# nrf9160 register map
Vendor: Nordic Semiconductor; Series: nrf91; File version: 1
CPU: CM33 r0p4, little endian, MPU, FPU, 3 interrupt priority bits, 69 interrupts
Registers are 32-bit, read-write, reset 0x0 unless marked. A register's access mark holds for its fields unless they carry their own. Offsets are from the block's base; [hi:lo] are bit positions; lines under a group give offsets from that group; {n}, {i} and the like mark numbered series; 'fields as' and 'values as' point back to an identical list.

## TAD_S — Trace and debug control
Base 0xE0080000
0x00 CLOCKSTART wo — Start all trace and debug clocks.
  [0] START
    1=Start all trace and debug clocks
0x04 CLOCKSTOP wo — Stop all trace and debug clocks.
  [0] STOP
    1=Stop all trace and debug clocks
0x500 ENABLE — Enable debug domain and acquire selected GPIOs
  [0] ENABLE
    0=DISABLED (Disable debug domain and release selected GPIOs); 1=ENABLED (Enable debug domain and acquire selected GPIOs)
0x504 PSEL group — Unspecified
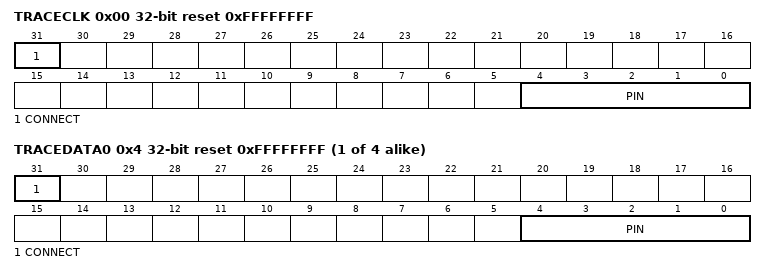
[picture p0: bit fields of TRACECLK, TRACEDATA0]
  0x00 TRACECLK reset 0xFFFFFFFF — Pin number configuration for TRACECLK
    [31] CONNECT — Connection
      1=Disconnected; 0=Connected
    [4:0] PIN — Pin number
  {0x4+4j} TRACEDATA{j} reset 0xFFFFFFFF (j=0..3) — Pin number configuration for TRACEDATA[{j}]
    fields as PSEL.TRACECLK
0x518 TRACEPORTSPEED — Clocking options for the Trace Port debug interface
  [1:0] TRACEPORTSPEED — Speed of Trace Port clock. Note that the TRACECLK pin will output this clock divided by two.
    0=32 MHz Trace Port clock (TRACECLK = 16 MHz); 1=16 MHz Trace Port clock (TRACECLK = 8 MHz); 2=8 MHz Trace Port clock (TRACECLK = 4 MHz); 3=4 MHz Trace Port clock (TRACECLK = 2 MHz)

## REGULATORS_NS — Voltage regulators control 0
Base 0x40004000
Same registers: REGULATORS_S 0x50004000
0x500 SYSTEMOFF wo
  [0] SYSTEMOFF — Enable System OFF mode
    1=Enable System OFF mode
0x578 DCDCEN — Enable DC/DC mode of the main voltage regulator.
  [0] DCDCEN — Enable DC/DC converter
    0=Disabled (DC/DC mode is disabled); 1=Enabled (DC/DC mode is enabled)

## POWER_NS — Power control 0
Base 0x40005000; alternate view of CLOCK_NS
Same registers: POWER_S 0x50005000 (alternate view of CLOCK_S)
0x78 TASKS_CONSTLAT wo — Enable constant latency mode.
  [0] TASKS_CONSTLAT
    1=Trigger task
0x7C TASKS_LOWPWR wo — Enable low power mode (variable latency)
  [0] TASKS_LOWPWR
    1=Trigger task
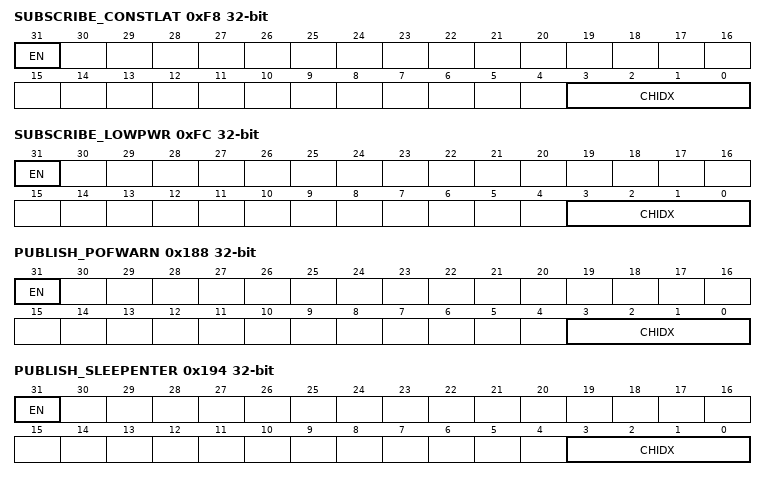
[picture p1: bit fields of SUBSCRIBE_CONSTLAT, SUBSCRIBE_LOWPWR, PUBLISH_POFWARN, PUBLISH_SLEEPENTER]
0xF8 SUBSCRIBE_CONSTLAT — Subscribe configuration for task CONSTLAT
  [31] EN
    0=Disabled (Disable subscription); 1=Enabled (Enable subscription)
  [3:0] CHIDX — Channel that task CONSTLAT will subscribe to
0xFC SUBSCRIBE_LOWPWR — Subscribe configuration for task LOWPWR
  [31] EN
    values as SUBSCRIBE_CONSTLAT.EN
  [3:0] CHIDX — Channel that task LOWPWR will subscribe to
0x108 EVENTS_POFWARN — Power failure warning
  [0] EVENTS_POFWARN
    0=NotGenerated (Event not generated); 1=Generated (Event generated)
0x114 EVENTS_SLEEPENTER — CPU entered WFI/WFE sleep
  [0] EVENTS_SLEEPENTER
    values as EVENTS_POFWARN.EVENTS_POFWARN
0x118 EVENTS_SLEEPEXIT — CPU exited WFI/WFE sleep
  [0] EVENTS_SLEEPEXIT
    values as EVENTS_POFWARN.EVENTS_POFWARN
0x188 PUBLISH_POFWARN — Publish configuration for event POFWARN
  [31] EN
    0=Disabled (Disable publishing); 1=Enabled (Enable publishing)
  [3:0] CHIDX — Channel that event POFWARN will publish to.
0x194 PUBLISH_SLEEPENTER — Publish configuration for event SLEEPENTER
  [31] EN
    values as PUBLISH_POFWARN.EN
  [3:0] CHIDX — Channel that event SLEEPENTER will publish to.
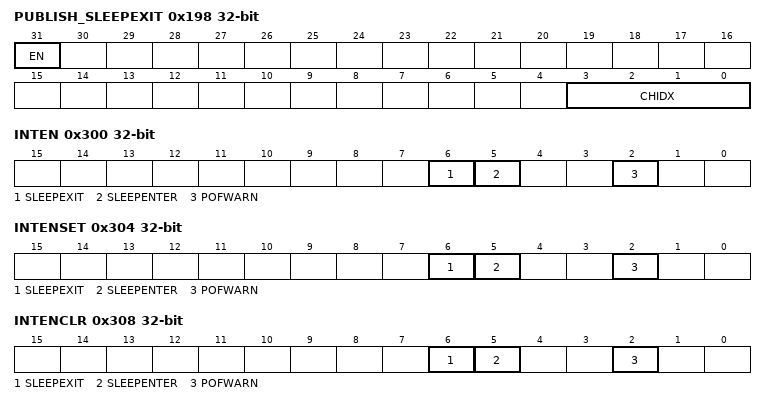
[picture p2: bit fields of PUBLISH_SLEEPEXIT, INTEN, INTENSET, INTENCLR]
0x198 PUBLISH_SLEEPEXIT — Publish configuration for event SLEEPEXIT
  [31] EN
    values as PUBLISH_POFWARN.EN
  [3:0] CHIDX — Channel that event SLEEPEXIT will publish to.
0x300 INTEN — Enable or disable interrupt
  [all] fields
    0=Disabled; 1=Enabled
  [6] SLEEPEXIT — Enable or disable interrupt for event SLEEPEXIT
  [5] SLEEPENTER — Enable or disable interrupt for event SLEEPENTER
  [2] POFWARN — Enable or disable interrupt for event POFWARN
0x304 INTENSET — Enable interrupt
  [all] fields
    on read: 0=Disabled (Read: Disabled); 1=Enabled (Read: Enabled) | on write: 1=Set (Enable)
  [6] SLEEPEXIT — Write '1' to enable interrupt for event SLEEPEXIT
  [5] SLEEPENTER — Write '1' to enable interrupt for event SLEEPENTER
  [2] POFWARN — Write '1' to enable interrupt for event POFWARN
0x308 INTENCLR — Disable interrupt
  [all] fields
    on read: 0=Disabled (Read: Disabled); 1=Enabled (Read: Enabled) | on write: 1=Clear (Disable)
  [6] SLEEPEXIT — Write '1' to disable interrupt for event SLEEPEXIT
  [5] SLEEPENTER — Write '1' to disable interrupt for event SLEEPENTER
  [2] POFWARN — Write '1' to disable interrupt for event POFWARN
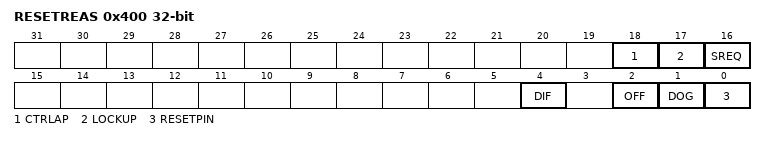
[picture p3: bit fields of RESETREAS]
0x400 RESETREAS — Reset reason
  [all] fields
    0=NotDetected; 1=Detected
  [18] CTRLAP — Reset triggered through CTRL-AP
  [17] LOCKUP — Reset from CPU lock-up detected
  [16] SREQ — Reset from AIRCR.SYSRESETREQ detected
  [4] DIF — Reset due to wakeup from System OFF mode, when wakeup is triggered by entering debug interface mode
  [2] OFF — Reset due to wakeup from System OFF mode, when wakeup is triggered by DETECT signal from GPIO
  [1] DOG — Reset from global watchdog detected
  [0] RESETPIN — Reset from pin reset detected
0x440 POWERSTATUS ro — Modem domain power status
  [0] LTEMODEM — LTE modem domain status
    0=OFF (LTE modem domain is powered off); 1=ON (LTE modem domain is powered on)
{0x51C+4i} GPREGRET[{i}] (i=0..1) — Description collection: General purpose retention register
  [7:0] GPREGRET — General purpose retention register

## Notices in the file
Copyright (c) 2010 - 2018, Nordic Semiconductor ASA All rights reserved.
Redistribution and use in source and binary forms, with or without
modification, are permitted provided that the following conditions are met:
1. Redistributions of source code must retain the above copyright notice, this
list of conditions and the following disclaimer.
2. Redistributions in binary form must reproduce the above copyright
notice, this list of conditions and the following disclaimer in the
documentation and/or other materials provided with the distribution.
3. Neither the name of Nordic Semiconductor ASA nor the names of its
contributors may be used to endorse or promote products derived from this
software without specific prior written permission.
THIS SOFTWARE IS PROVIDED BY THE COPYRIGHT HOLDERS AND CONTRIBUTORS "AS IS"
AND ANY EXPRESS OR IMPLIED WARRANTIES, INCLUDING, BUT NOT LIMITED TO, THE
IMPLIED WARRANTIES OF MERCHANTABILITY, AND FITNESS FOR A PARTICULAR PURPOSE
ARE DISCLAIMED. IN NO EVENT SHALL NORDIC SEMICONDUCTOR ASA OR CONTRIBUTORS BE
LIABLE FOR ANY DIRECT, INDIRECT, INCIDENTAL, SPECIAL, EXEMPLARY, OR
CONSEQUENTIAL DAMAGES (INCLUDING, BUT NOT LIMITED TO, PROCUREMENT OF
SUBSTITUTE GOODS OR SERVICES; LOSS OF USE, DATA, OR PROFITS; OR BUSINESS
INTERRUPTION) HOWEVER CAUSED AND ON ANY THEORY OF LIABILITY, WHETHER IN
CONTRACT, STRICT LIABILITY, OR TORT (INCLUDING NEGLIGENCE OR OTHERWISE)
ARISING IN ANY WAY OUT OF THE USE OF THIS SOFTWARE, EVEN IF ADVISED OF THE
POSSIBILITY OF SUCH DAMAGE.
